# MIK32 register map
Vendor: Mikron; Series: MIK32; File version: 1.0
Registers are 32-bit, read-write, reset 0x0 unless marked. A register's access mark holds for its fields unless they carry their own. Offsets are from the block's base; [hi:lo] are bit positions; {n}, {i} and the like mark numbered series; 'fields as' and 'values as' point back to an identical list.

## WDT — Сторожевой таймер
Base 0x00081000
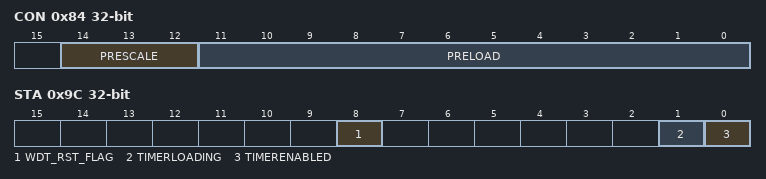
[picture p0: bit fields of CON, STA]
0x84 CON — Конфигурация
  [14:12] PRESCALE — Делитель входной частоты (Fclk) для таймера
    0=Fclk / 1; 1=Fclk / 2; 2=Fclk / 4; 3=Fclk / 16; 4=Fclk / 64; 5=Fclk / 256; 6=Fclk / 1024; 7=Fclk / 4096
  [11:0] PRELOAD — Начальное значение таймера при запуске или перезапуске (таймер считает в сторону увеличения значений)
0x9C KEY wo — Регистр ключа
0x9C STA ro — Регистр состояния
  [8] WDT_RST_FLAG — Флаг генерации сброса сторожевым таймером. Сбрасывается в 0 только при снятии и последующей подаче питания
  [1] TIMERLOADING rw — Бит перезагрузки значения
    0=Reloading_complete (Перезагрузка значения таймера в данный момент не выполняется (завершена)); 1=Reloading (Выполняется перезагрузка значения в таймере)
  [0] TIMERENABLED rw — Бит активности таймера
    0=Disable (Таймер остановлен); 1=Enable (Таймер запущен)

## TIMER32_1 — регистры модуля таймера_1
Base 0x00082800
0x00 VALUE
  [31:0] TIM_VAL ro — текущее значение счетчика
0x04 TOP reset 0xFFFFFFFF — максимальное значение счетной последовательности
  [31:0] TIM_TOP — максимальное значение счетчика (ограничивает счетную последоваельность сверху)
0x08 PRESCALE — значение делителя
  [31:0] TIM_PRESCALE — Значение предварительного делителя. Предделитель вырабатывает тактовый сигнал для счета, частота которого в целое раз меньше входной
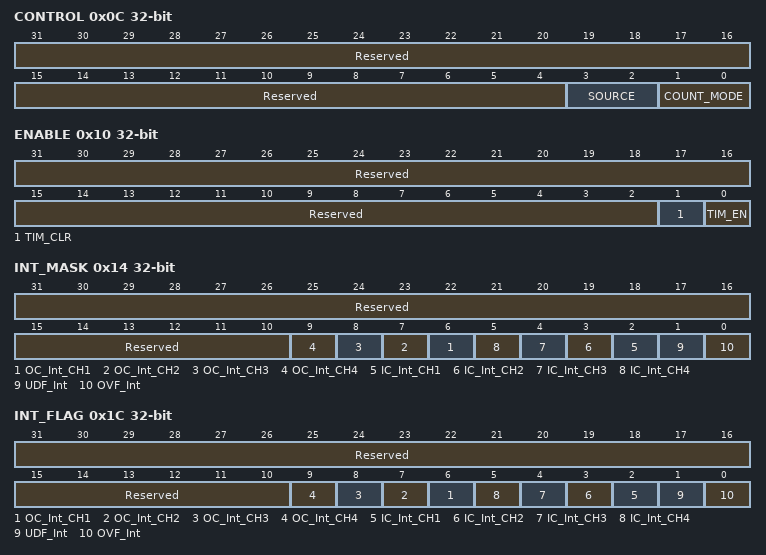
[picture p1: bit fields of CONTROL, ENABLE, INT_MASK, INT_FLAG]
0x0C CONTROL — Конфигурационный регистр основного таймера
  [31:4] Reserved — Зарезервировано
  [3:2] SOURCE — Выбор источника тактового сигнала для счёта
    0=PRESCALER (Выход предделителя); 1=TIM1 (Вход модуля TIM1); 2=TX_PIN (Внешний вход TX); 3=TIM2 (Вход модуля TIM2)
  [1:0] COUNT_MODE — Режим счёта таймера
    0=Direct (Прямой режим); 1=Reverse (Обратный режим); 2=Bidirectional (Двунаправленный режим)
0x10 ENABLE — Регистр включения таймера
  [31:2] Reserved — Зарезервировано
  [1] TIM_CLR write-once — Сброс (обнуление) текущего значения счетчика при записи «1»
  [0] TIM_EN — Запуск/остановка работы счетчика
    0=Disable (Счетчик выключен); 1=Enable (Счетчик работает)
0x14 INT_MASK — Регистр маски прерываний
  [31:10] Reserved — Зарезервировано
  [n+5] OC_Int_CH{n} (n=1..4) — Маска прерывания совпадения {n} канала таймера
  [n+1] IC_Int_CH{n} (n=1..4) — Маска прерывания захвата {n} канала таймера
  [1] UDF_Int — Маска прерывания опустошения счетчика
  [0] OVF_Int — Маска прерывания по переполнению счетчика
0x18 INT_CLEAR reset 0xFFFFFFFF — Регистр сброса флагов прерываний
0x1C INT_FLAG — Регистр флагов прерываний
  [31:10] Reserved — Зарезервировано
  [n+5] OC_Int_CH{n} ro (n=1..4) — Статус прерывания совпадения {n} канала таймера
  [n+1] IC_Int_CH{n} ro (n=1..4) — Статус прерывания захвата {n} канала таймера
  [1] UDF_Int ro — Статус прерывания опустошения счетчика
  [0] OVF_Int ro — Статус прерывания по переполнению счетчика
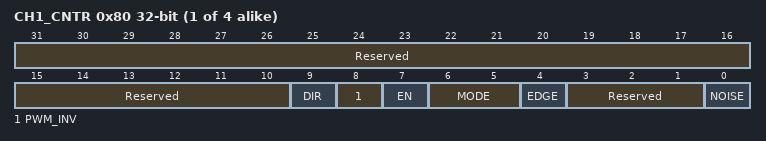
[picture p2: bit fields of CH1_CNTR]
{0x70+0x10*i} CH{i}_CNTR (i=1..4) — Конфигурационный регистр {i} канала
  [31:10] Reserved — Зарезервировано
  [9] DIR ro — Направление передачи данных. Устанавливается автоматически в зависимости от режима работы (1 - выход, 0 - вход)
    1=Output (Выход); 0=Input (Вход)
  [8] PWM_INV — Тип вывода в режиме ШИМ инвертирование
    1=Direct (Прямой (не инвертированный) выход); 0=Inverted (Инвертированный выход)
  [7] EN — Включение/выключение канала
  [6:5] MODE — Режим работы канала
    0=Reserved (Зарезервировано); 1=Compare (Режим сравнения (для timer0)); 2=Capture (Режим захвата(для timer0)); 3=PWM (ШИМ)
  [4] EDGE — Режим сигнала захвата
    0=Front (фронт); 1=Back (срез)
  [3:1] Reserved — Зарезервировано
  [0] NOISE — Управление фильтрацией входных помех на входе ic_port: 0 – фильтрация выклю-чена; 1 – фильтрация выклю-чена
    0=Enable (Фильтрация выключена); 1=Disable (Фильтрация включена)
{0x74+0x10*i} CH{i}_OCR (i=1..4) — Значение сравнения {i} канала
  [31:0] OCR — Значение таймера в режиме сравнения
{0x78+0x10*i} CH{i}_ICR (i=1..4) — Значение захвата {i} канала
  [31:0] ICR — Значение таймера в режиме захвата

## TIMER32_2 — регистры модуля таймера_2
Base 0x00082C00
Registers as TIMER32_1, without CH3_CNTR; these are added or differ:
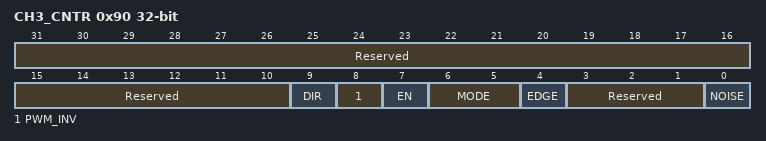
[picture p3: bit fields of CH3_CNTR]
0x90 CH3_CNTR — Конфигурационный регистр 3 канала
  fields as TIMER32_1.CH1_CNTR
